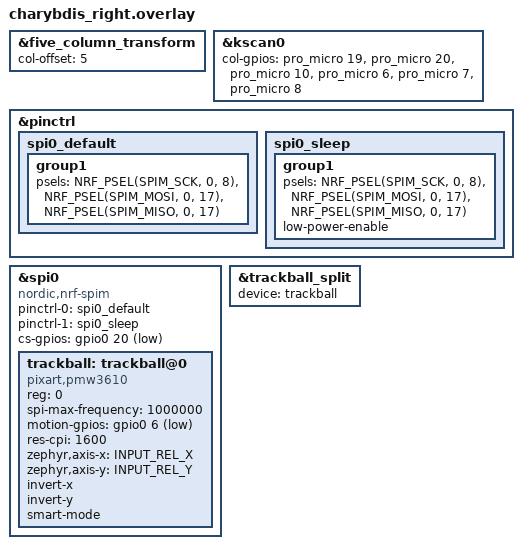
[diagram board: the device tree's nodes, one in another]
/*
 * Copyright (c) 2020 ZMK Contributors
 *
 * SPDX-License-Identifier: MIT
 */

#include "charybdis.dtsi"

&five_column_transform {
	col-offset = <5>;
};

&kscan0 {
	col-gpios
		= <&pro_micro 19 GPIO_ACTIVE_HIGH>
		, <&pro_micro 20 GPIO_ACTIVE_HIGH>
		, <&pro_micro 10 GPIO_ACTIVE_HIGH>
		, <&pro_micro 6 GPIO_ACTIVE_HIGH>
		, <&pro_micro 7 GPIO_ACTIVE_HIGH>
		, <&pro_micro 8 GPIO_ACTIVE_HIGH>
		;
};

&pinctrl {
    spi0_default: spi0_default {
        group1 {
            psels = <NRF_PSEL(SPIM_SCK, 0, 8)>,
                <NRF_PSEL(SPIM_MOSI, 0, 17)>,
                <NRF_PSEL(SPIM_MISO, 0, 17)>;
        };
    };

    spi0_sleep: spi0_sleep {
        group1 {
            psels = <NRF_PSEL(SPIM_SCK, 0, 8)>,
                <NRF_PSEL(SPIM_MOSI, 0, 17)>,
                <NRF_PSEL(SPIM_MISO, 0, 17)>;
            low-power-enable;
        };
    };
};

&spi0 {
    status = "okay";
    compatible = "nordic,nrf-spim";
    pinctrl-0 = <&spi0_default>;
    pinctrl-1 = <&spi0_sleep>;
    pinctrl-names = "default", "sleep";
    cs-gpios = <&gpio0 20 GPIO_ACTIVE_LOW>;

    trackball: trackball@0 {
        status = "okay";
        // Zephyr 4.1 업스트림 드라이버. badjeff fork(pixart,pmw3610-alt)와 달리
        // 모션 IRQ가 엣지 트리거라 "레벨 stuck → 인터럽트 폭주 → 반쪽 행" 경로가 없음.
        compatible = "pixart,pmw3610";
        reg = <0>;
        spi-max-frequency = <1000000>;
        // 모션 핀(=기존 irq-gpios). active-low.
        motion-gpios = <&gpio0 6 (GPIO_ACTIVE_LOW | GPIO_PULL_UP)>;
        // 기존 cpi=1000 그대로 (업스트림은 res-cpi 속성명).
        res-cpi = <1600>;
        // 기존 invert 유지. 업스트림은 zephyr,axis-* 사용.
        zephyr,axis-x = <INPUT_REL_X>;
        zephyr,axis-y = <INPUT_REL_Y>;
        invert-x;
        invert-y;
        // badjeff의 SMART_ALGORITHM(기본 on)과 동등하게 스마트 모드 유지.
        smart-mode;
    };
};

// ZMK 공식 split pointing 패턴: peripheral은 trackball_split에 실제 device를 연결만 함
// 이벤트는 split BLE를 통해 dongle의 trackball_listener로 forwarding됨
&trackball_split {
    status = "okay";
    device = <&trackball>;
};
